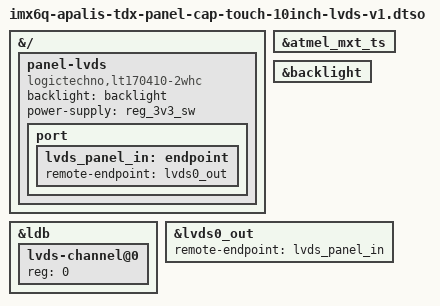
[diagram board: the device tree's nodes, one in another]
// SPDX-License-Identifier: GPL-2.0-only OR MIT
/*
 * Copyright (c) Toradex
 *
 * Toradex Capacitive Touch Display 10.1" connected via Apalis iMX6 LDB
 * on carrier boards with a Toradex standard LVDS display connector.
 *
 * https://docs.toradex.com/105952-10-1-inch-lvds-capacitive-touch-display-1280x800-datasheet.pdf
 * https://developer.toradex.com/hardware/accessories/displays/capacitive-touch-display-101inch-lvds
 * https://www.toradex.com/accessories/capacitive-touch-display-10.1-inch-lvds
 */

/dts-v1/;
/plugin/;

&{/} {
	panel-lvds {
		compatible = "logictechno,lt170410-2whc";
		backlight = <&backlight>;
		power-supply = <&reg_3v3_sw>;

		port {
			lvds_panel_in: endpoint {
				remote-endpoint = <&lvds0_out>;
			};
		};
	};
};

&atmel_mxt_ts {
	status = "okay";
};

&backlight {
	status = "okay";
};

&ldb {
	#address-cells = <1>;
	#size-cells = <0>;

	status = "okay";

	lvds-channel@0 {
		reg = <0>;

		status = "okay";
	};
};

&lvds0_out {
	remote-endpoint = <&lvds_panel_in>;
};
